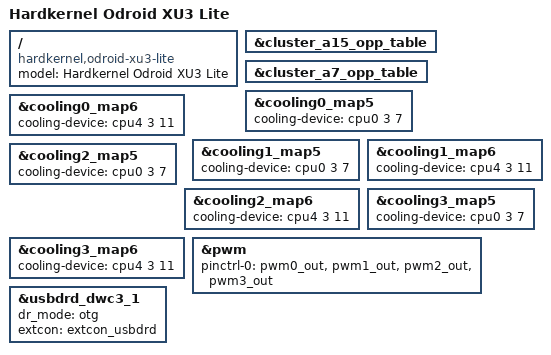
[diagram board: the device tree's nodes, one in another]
/*
 * Hardkernel Odroid XU3-Lite board device tree source
 *
 * Copyright (c) 2015 Krzysztof Kozlowski
 * Copyright (c) 2014 Collabora Ltd.
 * Copyright (c) 2013 Samsung Electronics Co., Ltd.
 *		http://www.samsung.com
 *
 * This program is free software; you can redistribute it and/or modify
 * it under the terms of the GNU General Public License version 2 as
 * published by the Free Software Foundation.
*/

/dts-v1/;
#include "exynos5422-odroidxu3-common.dtsi"
#include "exynos5422-odroidxu3-audio.dtsi"
#include "exynos54xx-odroidxu-leds.dtsi"

/ {
	model = "Hardkernel Odroid XU3 Lite";
	compatible = "hardkernel,odroid-xu3-lite", "samsung,exynos5800", "samsung,exynos5";
};

/*
 * Odroid XU3-Lite board uses SoC revision with lower maximum frequencies
 * than Odroid XU3/XU4 boards: 1.8 GHz for A15 cores & 1.3 GHz for A7 cores.
 * Therefore we need to update OPPs tables and thermal maps accordingly.
 */
&cluster_a15_opp_table {
	/delete-node/opp-2000000000;
	/delete-node/opp-1900000000;
};

&cluster_a7_opp_table {
	/delete-node/opp-1400000000;
};

&cooling0_map5 {
	cooling-device = <&cpu0 3 7>;
};

&cooling0_map6 {
	cooling-device = <&cpu4 3 11>;
};

&cooling1_map5 {
	cooling-device = <&cpu0 3 7>;
};

&cooling1_map6 {
	cooling-device = <&cpu4 3 11>;
};

&cooling2_map5 {
	cooling-device = <&cpu0 3 7>;
};

&cooling2_map6 {
	cooling-device = <&cpu4 3 11>;
};

&cooling3_map5 {
	cooling-device = <&cpu0 3 7>;
};

&cooling3_map6 {
	cooling-device = <&cpu4 3 11>;
};

&pwm {
	/*
	 * PWM 0 -- fan
	 * PWM 1 -- Green LED
	 * PWM 2 -- Blue LED
	 * PWM 3 -- on MIPI connector for backlight
	 */
	pinctrl-0 = <&pwm0_out &pwm1_out &pwm2_out &pwm3_out>;
	pinctrl-names = "default";
	status = "okay";
};

&usbdrd_dwc3_1 {
	dr_mode = "otg";
	extcon = <&extcon_usbdrd>;
};
